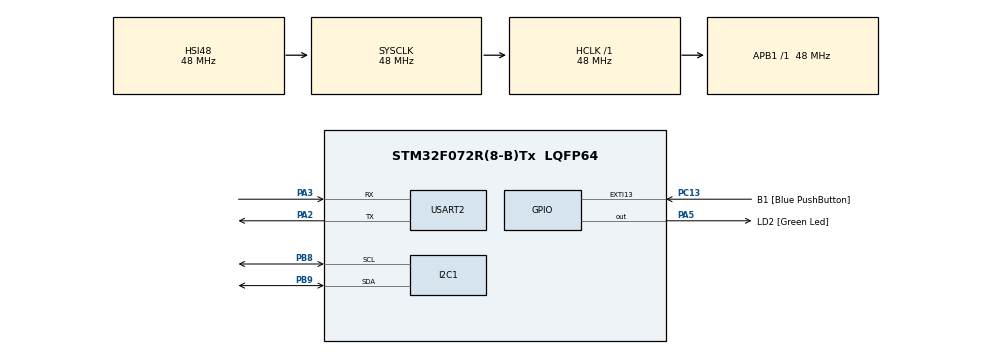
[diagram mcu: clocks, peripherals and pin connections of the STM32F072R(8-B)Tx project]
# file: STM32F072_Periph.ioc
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Dma.I2C1_RX.0.Direction=DMA_PERIPH_TO_MEMORY
Dma.I2C1_RX.0.Instance=DMA1_Channel3
Dma.I2C1_RX.0.MemDataAlignment=DMA_MDATAALIGN_BYTE
Dma.I2C1_RX.0.MemInc=DMA_MINC_ENABLE
Dma.I2C1_RX.0.Mode=DMA_NORMAL
Dma.I2C1_RX.0.PeriphDataAlignment=DMA_PDATAALIGN_BYTE
Dma.I2C1_RX.0.PeriphInc=DMA_PINC_DISABLE
Dma.I2C1_RX.0.Priority=DMA_PRIORITY_LOW
Dma.I2C1_TX.1.Direction=DMA_MEMORY_TO_PERIPH
Dma.I2C1_TX.1.Instance=DMA1_Channel2
Dma.I2C1_TX.1.MemDataAlignment=DMA_MDATAALIGN_BYTE
Dma.I2C1_TX.1.MemInc=DMA_MINC_ENABLE
Dma.I2C1_TX.1.Mode=DMA_NORMAL
Dma.I2C1_TX.1.PeriphDataAlignment=DMA_PDATAALIGN_BYTE
Dma.I2C1_TX.1.PeriphInc=DMA_PINC_DISABLE
Dma.I2C1_TX.1.Priority=DMA_PRIORITY_LOW
Dma.Request0=I2C1_RX
Dma.Request1=I2C1_TX
I2C1.OwnAddress=0x40
I2C1.Timing=0x20303E5D
Mcu.Family=STM32F0
Mcu.Name=STM32F072R(8-B)Tx
Mcu.Package=LQFP64
NVIC.DMA1_Channel2_3_IRQn=true\:0\:0\:false\:false\:true\:false
NVIC.I2C1_IRQn=true\:0\:0\:false\:false\:true\:true
NVIC.RCC_CRS_IRQn=true\:0\:0\:false\:false\:true\:true
NVIC.TIM7_IRQn=true\:0\:0\:false\:false\:true\:true
PA13.GPIO_Label=TMS
PA13.Mode=Serial_Wire
PA13.Signal=SYS_SWDIO
PA14.GPIO_Label=TCK
PA14.Mode=Serial_Wire
PA14.Signal=SYS_SWCLK
PA2.Mode=Asynchronous
PA2.Signal=USART2_TX
PA3.Mode=Asynchronous
PA3.Signal=USART2_RX
PA5.GPIO_Label=LD2 [Green Led]
PA5.GPIO_Mode=GPIO_MODE_OUTPUT_PP
PA5.GPIO_PuPd=GPIO_NOPULL
PA5.GPIO_Speed=GPIO_SPEED_FREQ_LOW
PA5.Signal=GPIO_Output
PB8.Mode=I2C
PB8.Signal=I2C1_SCL
PB9.Mode=I2C
PB9.Signal=I2C1_SDA
PC13.GPIO_Label=B1 [Blue PushButton]
PC13.GPIO_ModeDefaultEXTI=GPIO_MODE_IT_FALLING
PC13.Signal=GPXTI13
ProjectManager.HeapSize=0x200
ProjectManager.StackSize=0x400
ProjectManager.TargetToolchain=MDK-ARM V5
RCC.AHBFreq_Value=48000000
RCC.APB1Freq_Value=48000000
RCC.APB1TimFreq_Value=48000000
RCC.FLatency-AdvancedSettings=FLASH_LATENCY_1
RCC.HCLKFreq_Value=48000000
RCC.I2c1ClockSelection=RCC_I2C1CLKSOURCE_SYSCLK
RCC.PLLDivider=RCC_PREDIV_DIV2
RCC.PLLMUL=RCC_PLL_MUL12
RCC.PREFETCH_ENABLE=1
RCC.PREFETCH_ENABLE-AdvancedSettings=1
RCC.SYSCLKFreq_VALUE=48000000
RCC.SYSCLKSource=RCC_SYSCLKSOURCE_HSI48
TIM7.Period=63999
TIM7.Prescaler=191
USART2.VirtualMode-Asynchronous=VM_ASYNC
VP_TIM7_VS_ClockSourceINT.Mode=Enable_Timer
board=NUCLEO-F072RB

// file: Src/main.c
/**
  ******************************************************************************
  * @file           : main.c
  * @brief          : Main program body
  ******************************************************************************
  ** This notice applies to any and all portions of this file
  * that are not between comment pairs USER CODE BEGIN and
  * USER CODE END. Other portions of this file, whether
  * inserted by the user or by software development tools
  * are owned by their respective copyright owners.
  *
  * COPYRIGHT(c) 2019 STMicroelectronics
  *
  * Redistribution and use in source and binary forms, with or without modification,
  * are permitted provided that the following conditions are met:
  *   1. Redistributions of source code must retain the above copyright notice,
  *      this list of conditions and the following disclaimer.
  *   2. Redistributions in binary form must reproduce the above copyright notice,
  *      this list of conditions and the following disclaimer in the documentation
  *      and/or other materials provided with the distribution.
  *   3. Neither the name of STMicroelectronics nor the names of its contributors
  *      may be used to endorse or promote products derived from this software
  *      without specific prior written permission.
  *
  * THIS SOFTWARE IS PROVIDED BY THE COPYRIGHT HOLDERS AND CONTRIBUTORS "AS IS"
  * AND ANY EXPRESS OR IMPLIED WARRANTIES, INCLUDING, BUT NOT LIMITED TO, THE
  * IMPLIED WARRANTIES OF MERCHANTABILITY AND FITNESS FOR A PARTICULAR PURPOSE ARE
  * DISCLAIMED. IN NO EVENT SHALL THE COPYRIGHT HOLDER OR CONTRIBUTORS BE LIABLE
  * FOR ANY DIRECT, INDIRECT, INCIDENTAL, SPECIAL, EXEMPLARY, OR CONSEQUENTIAL
  * DAMAGES (INCLUDING, BUT NOT LIMITED TO, PROCUREMENT OF SUBSTITUTE GOODS OR
  * SERVICES; LOSS OF USE, DATA, OR PROFITS; OR BUSINESS INTERRUPTION) HOWEVER
  * CAUSED AND ON ANY THEORY OF LIABILITY, WHETHER IN CONTRACT, STRICT LIABILITY,
  * OR TORT (INCLUDING NEGLIGENCE OR OTHERWISE) ARISING IN ANY WAY OUT OF THE USE
  * OF THIS SOFTWARE, EVEN IF ADVISED OF THE POSSIBILITY OF SUCH DAMAGE.
  *
  ******************************************************************************
  */
#include "main.h"
#include "stm32f0xx_hal.h"
#include "dma.h"
#include "i2c.h"
#include "tim.h"
#include "usart.h"
#include "gpio.h"

/* USER CODE BEGIN Includes */
#include "testhelpers.h"
#include "example.h"
/* USER CODE END Includes */

/* USER CODE BEGIN PV */
/* Private variables ---------------------------------------------------------*/

/* USER CODE END PV */

void SystemClock_Config(void);

/* USER CODE BEGIN PFP */
/* Private function prototypes -----------------------------------------------*/

/* USER CODE END PFP */

int main(void)
{
  /* USER CODE BEGIN 1 */
  DOTT_test_hook();
  /* USER CODE END 1 */

  /* MCU Configuration----------------------------------------------------------*/

  /* Reset of all peripherals, Initializes the Flash interface and the Systick. */
  HAL_Init();

  /* Configure the system clock */
  SystemClock_Config();

  /* Initialize all configured peripherals */
  MX_GPIO_Init();
  MX_DMA_Init();
  MX_I2C1_Init();
  MX_USART2_UART_Init();
  MX_TIM7_Init();

  /* Infinite loop */
  /* USER CODE BEGIN WHILE */
  HAL_TIM_Base_Start_IT(&htim7);

  while (1)
  {
    app_main();
  /* USER CODE END WHILE */

  }

}

void SystemClock_Config(void)
{

  RCC_OscInitTypeDef RCC_OscInitStruct;
  RCC_ClkInitTypeDef RCC_ClkInitStruct;
  RCC_PeriphCLKInitTypeDef PeriphClkInit;

    /**Initializes the CPU, AHB and APB busses clocks
    */
  RCC_OscInitStruct.OscillatorType = RCC_OSCILLATORTYPE_HSI48;
  RCC_OscInitStruct.HSI48State = RCC_HSI48_ON;
  RCC_OscInitStruct.PLL.PLLState = RCC_PLL_NONE;
  if (HAL_RCC_OscConfig(&RCC_OscInitStruct) != HAL_OK)
  {
    _Error_Handler(__FILE__, __LINE__);
  }

    /**Initializes the CPU, AHB and APB busses clocks
    */
  RCC_ClkInitStruct.ClockType = RCC_CLOCKTYPE_HCLK|RCC_CLOCKTYPE_SYSCLK
                              |RCC_CLOCKTYPE_PCLK1;
  RCC_ClkInitStruct.SYSCLKSource = RCC_SYSCLKSOURCE_HSI48;
  RCC_ClkInitStruct.AHBCLKDivider = RCC_SYSCLK_DIV1;
  RCC_ClkInitStruct.APB1CLKDivider = RCC_HCLK_DIV1;

  if (HAL_RCC_ClockConfig(&RCC_ClkInitStruct, FLASH_LATENCY_1) != HAL_OK)
  {
    _Error_Handler(__FILE__, __LINE__);
  }

  PeriphClkInit.PeriphClockSelection = RCC_PERIPHCLK_USART2|RCC_PERIPHCLK_I2C1;
  PeriphClkInit.Usart2ClockSelection = RCC_USART2CLKSOURCE_PCLK1;
  PeriphClkInit.I2c1ClockSelection = RCC_I2C1CLKSOURCE_SYSCLK;
  if (HAL_RCCEx_PeriphCLKConfig(&PeriphClkInit) != HAL_OK)
  {
    _Error_Handler(__FILE__, __LINE__);
  }

    /**Configure the Systick interrupt time
    */
  HAL_SYSTICK_Config(HAL_RCC_GetHCLKFreq()/1000);

    /**Configure the Systick
    */
  HAL_SYSTICK_CLKSourceConfig(SYSTICK_CLKSOURCE_HCLK);

  /* SysTick_IRQn interrupt configuration */
  HAL_NVIC_SetPriority(SysTick_IRQn, 0, 0);
}

void _Error_Handler(char *file, int line)
{
  while(1)
  {
  }
}

/************************ (C) COPYRIGHT STMicroelectronics *****END OF FILE****/
